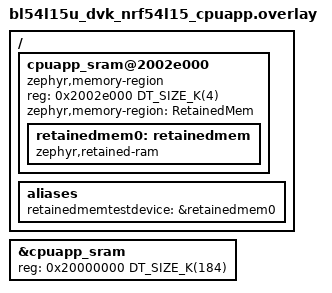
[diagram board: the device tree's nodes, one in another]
/*
 * Copyright (c) 2024 Nordic Semiconductor ASA
 * Copyright (c) 2025 Ezurio LLC
 *
 * SPDX-License-Identifier: Apache-2.0
 */

/ {
	cpuapp_sram@2002e000 {
		compatible = "zephyr,memory-region", "mmio-sram";
		reg = <0x2002e000 DT_SIZE_K(4)>;
		zephyr,memory-region = "RetainedMem";
		status = "okay";

		retainedmem0: retainedmem {
			compatible = "zephyr,retained-ram";
			status = "okay";
		};
	};

	aliases {
		retainedmemtestdevice = &retainedmem0;
	};
};

&cpuapp_sram {
	reg = <0x20000000 DT_SIZE_K(184)>;
	ranges = <0x0 0x20000000 0x2e000>;
};
